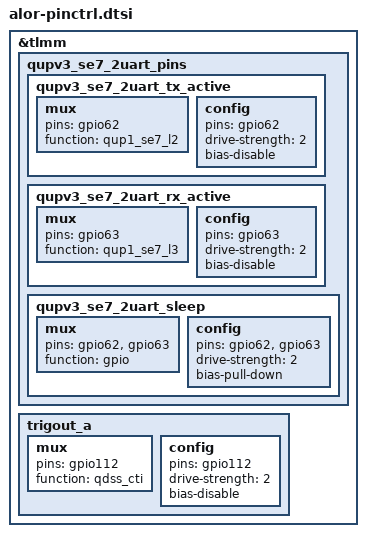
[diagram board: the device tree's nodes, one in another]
// SPDX-License-Identifier: BSD-3-Clause
/*
 * Copyright (c) 2024-2025 Qualcomm Innovation Center, Inc. All rights reserved.
 */

&tlmm {
	qupv3_se7_2uart_pins: qupv3_se7_2uart_pins {
		qupv3_se7_2uart_tx_active: qupv3_se7_2uart_tx_active {
			mux {
				pins = "gpio62";
				function = "qup1_se7_l2";
			};

			config {
				pins = "gpio62";
				drive-strength = <2>;
				bias-disable;
			};
		};

		qupv3_se7_2uart_rx_active: qupv3_se7_2uart_rx_active {
			mux {
				pins = "gpio63";
				function = "qup1_se7_l3";
			};

			config {
				pins = "gpio63";
				drive-strength = <2>;
				bias-disable;
			};
		};

		qupv3_se7_2uart_sleep: qupv3_se7_2uart_sleep {
			mux {
				pins = "gpio62", "gpio63";
				function = "gpio";
			};

			config {
				pins = "gpio62", "gpio63";
				drive-strength = <2>;
				bias-pull-down;
			};
		};
	};

	trigout_a: trigout_a {
		mux {
			pins = "gpio112";
			function = "qdss_cti";
		};

		config {
			pins = "gpio112";
			drive-strength = <2>;
			bias-disable;
		};
	};
};
